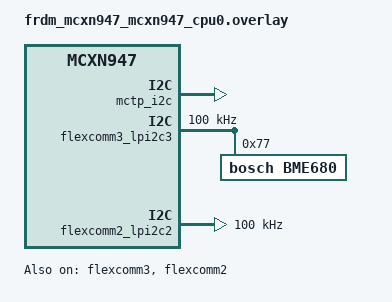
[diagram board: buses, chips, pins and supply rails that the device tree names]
/*
 * Copyright (c) 2025 Intel Corporation
 *
 * SPDX-License-Identifier: Apache-2.0
 */

#include <zephyr/dt-bindings/i2c/i2c.h>

/delete-node/ &lpcmp0;

&flexcomm3 {
	status = "okay";
};

&flexcomm3_lpi2c3 {
	status = "okay";
	pinctrl-0 = <&pinmux_flexcomm3_lpi2c>;
	pinctrl-names = "default";
	clock-frequency = <I2C_BITRATE_STANDARD>;
	bme680: bme680@77 {
		compatible = "bosch,bme680";
		reg = <0x77>;
		status = "okay";
	};
};

&nxp_lcd_8080_connector {
	status = "disabled";
};

&flexio0 {
	status = "disabled";
};

&gpio0 {
	status = "okay";
};

&flexcomm2 {
	status = "okay";
};

&flexcomm2_lpi2c2 {
	status = "okay";
	clock-frequency = <I2C_BITRATE_STANDARD>;
};


/ {
	mctp_i2c: mctp_i2c {
		compatible = "zephyr,mctp-i2c-gpio-target";
		i2c = <&flexcomm2_lpi2c2>;
		i2c-addr = <70>;
		endpoint-id = <11>;
		endpoint-gpios = <&gpio0 7 GPIO_ACTIVE_HIGH>;
	};
};
